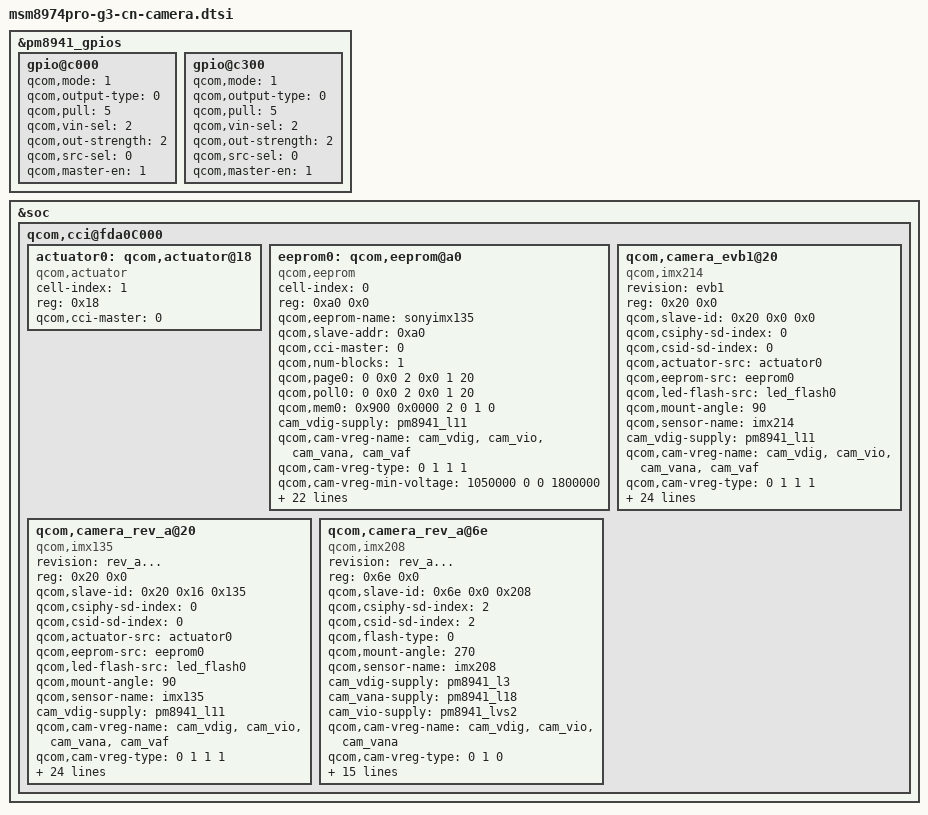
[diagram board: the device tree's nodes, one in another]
/*
 * Copyright (c) 2012, The Linux Foundation. All rights reserved.
 *
 * This program is free software; you can redistribute it and/or modify
 * it under the terms of the GNU General Public License version 2 and
 * only version 2 as published by the Free Software Foundation.
 *
 * This program is distributed in the hope that it will be useful,
 * but WITHOUT ANY WARRANTY; without even the implied warranty of
 * MERCHANTABILITY or FITNESS FOR A PARTICULAR PURPOSE.  See the
 * GNU General Public License for more details.
 */

/include/ "../../../skeleton.dtsi"

&pm8941_gpios {
	gpio@c000 { /* GPIO 1 */
		status = "ok";			/* LDAF_EN */
		qcom,mode = <1>;		/* QPNP_PIN_MODE_DIG_OUT */
		qcom,output-type = <0>;		/* QPNP_PIN_OUT_BUF_CMOS */
		qcom,pull = <5>;		/* QPNP_PIN_PULL_NO */
		qcom,vin-sel = <2>;		/* QPNP_PIN_VIN2 */
		qcom,out-strength = <2>;	/* QPNP_PIN_OUT_STRENGTH_MED */
		qcom,src-sel = <0>;		/* QPNP_PIN_SEL_FUNC_CONSTANT */
		qcom,master-en = <1>;
	};

	gpio@c300 { /* GPIO 4 */
		status = "ok";			/* CAMERA VCM */
		qcom,mode = <1>;		/* QPNP_PIN_MODE_DIG_OUT */
		qcom,output-type = <0>;		/* QPNP_PIN_OUT_BUF_CMOS */
		qcom,pull = <5>;		/* QPNP_PIN_PULL_NO */
		qcom,vin-sel = <2>;		/* QPNP_PIN_VIN2 */
		qcom,out-strength = <2>;	/* QPNP_PIN_OUT_STRENGTH_MED */
		qcom,src-sel = <0>;		/* QPNP_PIN_SEL_FUNC_CONSTANT */
		qcom,master-en = <1>;
	};
};

&soc {
	qcom,cci@fda0C000 {
		actuator0: qcom,actuator@18 {
			cell-index = <1>;//Use Af_main_1 of dw9714
			reg = <0x18>;
			compatible = "qcom,actuator";
			qcom,cci-master = <0>;
		};

		eeprom0: qcom,eeprom@a0 {
			cell-index = <0>;
			reg = <0xa0 0x0>;
			qcom,eeprom-name = "sonyimx135";
			compatible = "qcom,eeprom";
			qcom,slave-addr = <0xa0>;
			qcom,cci-master = <0>;
			qcom,num-blocks = <1>;
			qcom,page0 = <0 0x0 2 0x0 1 20>;
			qcom,poll0 = <0 0x0 2 0x0 1 20>;
			qcom,mem0 = <0x900 0x0000 2 0 1 0>; //EEPROM READ

			cam_vdig-supply = <&pm8941_l11>;
			qcom,cam-vreg-name = "cam_vdig", "cam_vio", "cam_vana", "cam_vaf";
			qcom,cam-vreg-type = <0 1 1 1 >;
			qcom,cam-vreg-min-voltage = <1050000 0 0 1800000>;
			qcom,cam-vreg-max-voltage = <1050000 0 0 1800000>;
			qcom,cam-vreg-op-mode = <105000 0 0 100000>;
			qcom,gpio-no-mux = <0>;
			gpios = <&msmgpio 15 0>, 		// MCLK
				<&msmgpio 4 0>,			// MAIN_CAM_RESET
				<&msmgpio 16 0>,			// 13M_VANA_EN
				<&msmgpio 96 0>,			// 13M_VIO_EN
				<&msmgpio 145 0>,			// 13M_VCM_EN : OIS_MVDD
				<&msmgpio 30 0>,		// OIS_LDO_EN : OIS_VDD
				<&msmgpio 29 0>,		// OIS_RESET
				<&pm8941_gpios 1 0>;	// LDAF_EN
			qcom,gpio-reset = <1>; 		// Set gpio_4 as reset
			qcom,gpio-vana = <2>;		// Set gpio_16 as VANA
			qcom,gpio-vio = <3>;			// Set gpio_96 as VIO
			qcom,gpio-vaf = <4>;			// Set pm8941_gpio_4 as VCM
			qcom,gpio-ois-ldo = <5>;		// Set gpio_145 as OIS_LDO_EN
			qcom,gpio-ois-reset = <6>;		// Set gpio_29 as OIS_RESET
			qcom,gpio-ldaf-en = <7>;		// Set gpio_29 as OIS_RESET
			qcom,gpio-req-tbl-num = <0 1 2 3 4 5 6 7>;
			qcom,gpio-req-tbl-flags = <0 0 0 0 0 0 0 0>;
			qcom,gpio-req-tbl-label =  "CAMIF_MCLK", "CAM_RESET1", "MAIN_VANA_EN", "MAIN_VIO_EN", "MAIN_VCM_EN",
										"OIS_LDO_EN", "OIS_RESET", "LDAF_EN";

			qcom,cam-power-seq-type = "sensor_gpio";	// VIO
			qcom,cam-power-seq-val = "sensor_gpio_vio";
			qcom,cam-power-seq-cfg-val = <1>;
			qcom,cam-power-seq-delay = <20>;
		};

		qcom,camera_evb1@20 {
			status = "ok";
			revision = "evb1";
			compatible = "qcom,imx214";
			reg = <0x20 0x0>;
			qcom,slave-id = <0x20 0x0 0x0>;
			qcom,csiphy-sd-index = <0>;
			qcom,csid-sd-index = <0>;
			qcom,actuator-src = <&actuator0>;
			qcom,eeprom-src = <&eeprom0>; //Read EEPROM
			qcom,led-flash-src = <&led_flash0>;
			qcom,mount-angle = <90>;
			qcom,sensor-name = "imx214";
			cam_vdig-supply = <&pm8941_l11>;
			qcom,cam-vreg-name = "cam_vdig", "cam_vio", "cam_vana", "cam_vaf";
			qcom,cam-vreg-type = <0 1 1 1 >;
			qcom,cam-vreg-min-voltage = <1000000 0 0 1800000>;
			qcom,cam-vreg-max-voltage = <1000000 0 0 1800000>;
			qcom,cam-vreg-op-mode = <105000 0 0 100000>;
			qcom,gpio-no-mux = <0>;
			gpios = <&msmgpio 15 0>, 		// MCLK
				<&msmgpio 49 0>,			// MAIN_CAM_RESET
				<&msmgpio 16 0>,			// 13M_VANA_EN
				<&msmgpio 96 0>,			// 13M_VIO_EN
				<&msmgpio 57 0>,			// 13M_VCM_EN
				<&msmgpio 145 0>,		// OIS_LDO_EN
				<&msmgpio 30 0>,		// AF_MVDD
				<&msmgpio 29 0>;		// OIS_RESET
			qcom,gpio-reset = <1>; 		// Set gpio_4 as reset
			qcom,gpio-vana = <2>;		// Set gpio_16 as VANA
			qcom,gpio-vio = <3>;			// Set gpio_96 as VIO
			qcom,gpio-vaf = <4>;			// Set gpio_57 as VCM
			qcom,gpio-ois-ldo = <5>;		// Set gpio_145 as OIS_LDO_EN
			qcom,gpio-af_mvdd = <6>;		// Set gpio_30 as AF_MVDD
			qcom,gpio-ois-reset = <7>;		// Set gpio_29 as OIS_RESET
			qcom,gpio-req-tbl-num = <0 1 2 3 4 5 6 7>;
			qcom,gpio-req-tbl-flags = <0 0 0 0 0 0 0 0>;
			qcom,gpio-req-tbl-label =  "CAMIF_MCLK", "CAM_RESET1", "MAIN_VANA_EN", "MAIN_VIO_EN", "MAIN_VCM_EN", 
										"OIS_LDO_EN", "AF_MVDD", "OIS_RESET";
			qcom,csi-lane-assign = <0x4320>;
			qcom,csi-lane-mask = <0x1F>;
			qcom,sensor-position = <0>;
			qcom,sensor-mode = <0>;
			qcom,cci-master = <0>;
		};

		qcom,camera_rev_a@20 {
			status = "ok";
			compatible = "qcom,imx135";
			revision = "rev_a...";
			reg = <0x20 0x0>;
			qcom,slave-id = <0x20 0x16 0x135>;
			qcom,csiphy-sd-index = <0>;
			qcom,csid-sd-index = <0>;
			qcom,actuator-src = <&actuator0>;
			qcom,eeprom-src = <&eeprom0>; //Read EEPROM
			qcom,led-flash-src = <&led_flash0>;
			qcom,mount-angle = <90>;
			qcom,sensor-name = "imx135";
			cam_vdig-supply = <&pm8941_l11>;
			qcom,cam-vreg-name = "cam_vdig", "cam_vio", "cam_vana", "cam_vaf";
			qcom,cam-vreg-type = <0 1 1 1 >;
			qcom,cam-vreg-min-voltage = <1050000 0 0 1800000>;
			qcom,cam-vreg-max-voltage = <1050000 0 0 1800000>;
			qcom,cam-vreg-op-mode = <105000 0 0 100000>;
			qcom,gpio-no-mux = <0>;
			gpios = <&msmgpio 15 0>, 		// MCLK
				<&msmgpio 4 0>,			// MAIN_CAM_RESET
				<&msmgpio 16 0>,			// 13M_VANA_EN
				<&msmgpio 96 0>,			// 13M_VIO_EN
				<&msmgpio 145 0>,			// 13M_VCM_EN : OIS_MVDD
				<&msmgpio 30 0>,		// OIS_LDO_EN : OIS_VDD
				<&msmgpio 29 0>,		// OIS_RESET
				<&pm8941_gpios 1 0>;	// LDAF_EN
			qcom,gpio-reset = <1>; 		// Set gpio_4 as reset
			qcom,gpio-vana = <2>;		// Set gpio_16 as VANA
			qcom,gpio-vio = <3>;			// Set gpio_96 as VIO
			qcom,gpio-vaf = <4>;			// Set pm8941_gpio_4 as VCM
			qcom,gpio-ois-ldo = <5>;		// Set gpio_145 as OIS_LDO_EN
			qcom,gpio-ois-reset = <6>;		// Set gpio_29 as OIS_RESET
			qcom,gpio-ldaf-en = <7>;		// Set gpio_29 as OIS_RESET			
			qcom,gpio-req-tbl-num = <0 1 2 3 4 5 6 7>;
			qcom,gpio-req-tbl-flags = <0 0 0 0 0 0 0 0>;
			qcom,gpio-req-tbl-label =  "CAMIF_MCLK", "CAM_RESET1", "MAIN_VANA_EN", "MAIN_VIO_EN", "MAIN_VCM_EN",
										"OIS_LDO_EN", "OIS_RESET", "LDAF_EN";
			qcom,csi-lane-assign = <0x4320>;
			qcom,csi-lane-mask = <0x1F>;
			qcom,sensor-position = <0>;
			qcom,sensor-mode = <0>;
			qcom,cci-master = <0>;
		};

		qcom,camera_rev_a@6e {
			status = "ok";
			compatible = "qcom,imx208";
			revision = "rev_a...";
			reg = <0x6e 0x0>;
			qcom,slave-id = <0x6e 0x0 0x208>;
			qcom,csiphy-sd-index = <2>;
			qcom,csid-sd-index = <2>;
			qcom,flash-type = <0>;
			qcom,mount-angle = <270>;
			qcom,sensor-name = "imx208";
			cam_vdig-supply = <&pm8941_l3>;
			cam_vana-supply = <&pm8941_l18>;
			cam_vio-supply = <&pm8941_lvs2>;
			qcom,cam-vreg-name = "cam_vdig", "cam_vio", "cam_vana";
			qcom,cam-vreg-type = <0 1 0>;
			qcom,cam-vreg-min-voltage = <1200000 0 2700000>;
			qcom,cam-vreg-max-voltage = <1200000 0 2700000>;
			qcom,cam-vreg-op-mode = <1200000 0 2700000>;
			qcom,gpio-no-mux = <0>;
			gpios = <&msmgpio 17 0>, //VT_CAM_MCLK
				<&msmgpio 18 0>; //VT_CAM_RESET
			qcom,gpio-reset = <1>;
			qcom,gpio-req-tbl-num = <0 1>;
			qcom,gpio-req-tbl-flags = <0 0>;
			qcom,gpio-req-tbl-label = "CAMIF_MCLK2", "CAM_RESET2";
			qcom,csi-lane-assign = <0x4320>;
			qcom,csi-lane-mask = <0x3>;
			qcom,sensor-position = <1>;
			qcom,sensor-mode = <1>;
			qcom,cci-master = <1>;
		};

	};
};
